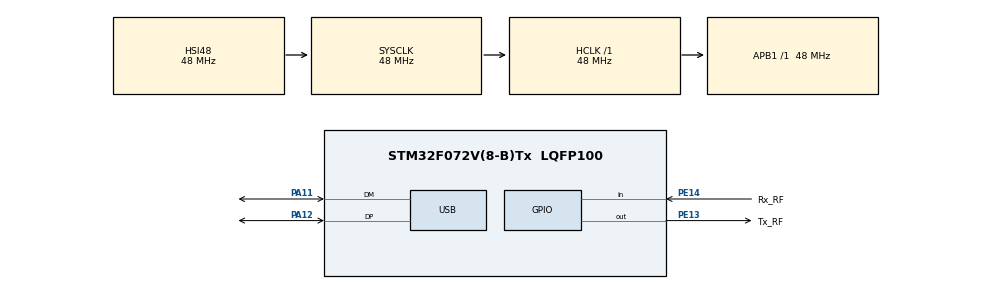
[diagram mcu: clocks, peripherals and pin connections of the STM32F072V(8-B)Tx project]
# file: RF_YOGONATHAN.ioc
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Mcu.Family=STM32F0
Mcu.Name=STM32F072V(8-B)Tx
Mcu.Package=LQFP100
NVIC.TIM7_IRQn=true\:0\:0\:false\:false\:true\:true\:true\:true
NVIC.USB_IRQn=true\:0\:0\:false\:false\:true\:false\:true\:true
PA11.Mode=Device
PA11.Signal=USB_DM
PA12.Mode=Device
PA12.Signal=USB_DP
PE13.GPIO_Label=Tx_RF
PE13.Signal=GPIO_Output
PE14.GPIO_Label=Rx_RF
PE14.Signal=GPIO_Input
ProjectManager.HeapSize=0x200
ProjectManager.StackSize=0x400
ProjectManager.TargetToolchain=STM32CubeIDE
RCC.AHBFreq_Value=48000000
RCC.APB1Freq_Value=48000000
RCC.APB1TimFreq_Value=48000000
RCC.HCLKFreq_Value=48000000
RCC.PLLSourceVirtual=RCC_PLLSOURCE_HSI48
RCC.SYSCLKFreq_VALUE=48000000
RCC.SYSCLKSource=RCC_SYSCLKSOURCE_HSI48
TIM7.Period=2975
USB_DEVICE.CLASS_NAME_FS=CDC
USB_DEVICE.VirtualMode=Cdc
USB_DEVICE.VirtualModeFS=Cdc_FS
VP_TIM7_VS_ClockSourceINT.Mode=Enable_Timer
VP_USB_DEVICE_VS_USB_DEVICE_CDC_FS.Mode=CDC_FS
board=custom

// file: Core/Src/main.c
/* USER CODE BEGIN Header */
/**
  ******************************************************************************
  * @file           : main.c
  * @brief          : Main program body
  ******************************************************************************
  * @attention
  *
  * Copyright (c) 2023 STMicroelectronics.
  * All rights reserved.
  *
  * This software is licensed under terms that can be found in the LICENSE file
  * in the root directory of this software component.
  * If no LICENSE file comes with this software, it is provided AS-IS.
  *
  ******************************************************************************
  */
/* USER CODE END Header */
#include "main.h"
#include "usb_device.h"

/* USER CODE BEGIN Includes */
#include "stdio.h"
#include "RH_ASK.h"

/* USER CODE END Includes */

TIM_HandleTypeDef htim7;

/* USER CODE BEGIN PV */

volatile uint32_t g_timerCount = 0;

uint32_t Count = 0;
uint8_t len=0, aMsgBuf[50] = {0};

uint8_t buf[RH_ASK_MAX_MESSAGE_LEN] = {0};
uint8_t buflen = 0;

/* USER CODE END PV */

void SystemClock_Config(void);
static void MX_GPIO_Init(void);
static void MX_TIM7_Init(void);

int main(void)
{

  /* MCU Configuration--------------------------------------------------------*/

  /* Reset of all peripherals, Initializes the Flash interface and the Systick. */
  HAL_Init();

  /* Configure the system clock */
  SystemClock_Config();

  /* Initialize all configured peripherals */
  MX_GPIO_Init();
  MX_TIM7_Init();
  MX_USB_DEVICE_Init();
  /* USER CODE BEGIN 2 */
  HAL_TIM_Base_Start_IT(&htim7);
//  HAL_UART_Transmit(&huart2, (uint8_t *)"/--------------------------------------------------------------/\r", 65, 1000);
//  HAL_UART_Transmit(&huart2, (uint8_t *)"               RF 433Mhz Receiver Test Application              \r", 65, 1000);
//  HAL_UART_Transmit(&huart2, (uint8_t *)"/--------------------------------------------------------------/\r", 65, 1000);

  RH_ASK_Initialization();

  /* USER CODE END 2 */

  /* Infinite loop */
  /* USER CODE BEGIN WHILE */

  char terminator[] = "\r\n";
  while (1)
  {
    /* USER CODE END WHILE */

    /* USER CODE BEGIN 3 */

	 // RH_send((uint8_t *)"Hello World\n", 12);
	  //HAL_Delay(2000);

	  buflen = RH_ASK_MAX_MESSAGE_LEN;
	  if(RH_recv(buf, &buflen) == True) {
//
//		  HAL_UART_Transmit(&huart2, (uint8_t *)"rxBuf :", 7, 1000);
//		  HAL_UART_Transmit(&huart2, (uint8_t *)buf, buflen, 1000);

		  CDC_Transmit_FS(buf, buflen);
		  CDC_Transmit_FS(terminator, sizeof(terminator));

  }
//	  HAL_Delay(1);
  }

  /* USER CODE END 3 */
}

void SystemClock_Config(void)
{
  RCC_OscInitTypeDef RCC_OscInitStruct = {0};
  RCC_ClkInitTypeDef RCC_ClkInitStruct = {0};
  RCC_PeriphCLKInitTypeDef PeriphClkInit = {0};

  /** Initializes the RCC Oscillators according to the specified parameters
  * in the RCC_OscInitTypeDef structure.
  */
  RCC_OscInitStruct.OscillatorType = RCC_OSCILLATORTYPE_HSI48;
  RCC_OscInitStruct.HSI48State = RCC_HSI48_ON;
  RCC_OscInitStruct.PLL.PLLState = RCC_PLL_NONE;
  if (HAL_RCC_OscConfig(&RCC_OscInitStruct) != HAL_OK)
  {
    Error_Handler();
  }

  /** Initializes the CPU, AHB and APB buses clocks
  */
  RCC_ClkInitStruct.ClockType = RCC_CLOCKTYPE_HCLK|RCC_CLOCKTYPE_SYSCLK
                              |RCC_CLOCKTYPE_PCLK1;
  RCC_ClkInitStruct.SYSCLKSource = RCC_SYSCLKSOURCE_HSI48;
  RCC_ClkInitStruct.AHBCLKDivider = RCC_SYSCLK_DIV1;
  RCC_ClkInitStruct.APB1CLKDivider = RCC_HCLK_DIV1;

  if (HAL_RCC_ClockConfig(&RCC_ClkInitStruct, FLASH_LATENCY_1) != HAL_OK)
  {
    Error_Handler();
  }
  PeriphClkInit.PeriphClockSelection = RCC_PERIPHCLK_USB;
  PeriphClkInit.UsbClockSelection = RCC_USBCLKSOURCE_HSI48;

  if (HAL_RCCEx_PeriphCLKConfig(&PeriphClkInit) != HAL_OK)
  {
    Error_Handler();
  }
}

static void MX_TIM7_Init(void)
{

  TIM_MasterConfigTypeDef sMasterConfig = {0};

  htim7.Instance = TIM7;
  htim7.Init.Prescaler = 0;
  htim7.Init.CounterMode = TIM_COUNTERMODE_UP;
  htim7.Init.Period = 2975;
  htim7.Init.AutoReloadPreload = TIM_AUTORELOAD_PRELOAD_DISABLE;
  if (HAL_TIM_Base_Init(&htim7) != HAL_OK)
  {
    Error_Handler();
  }
  sMasterConfig.MasterOutputTrigger = TIM_TRGO_RESET;
  sMasterConfig.MasterSlaveMode = TIM_MASTERSLAVEMODE_DISABLE;
  if (HAL_TIMEx_MasterConfigSynchronization(&htim7, &sMasterConfig) != HAL_OK)
  {
    Error_Handler();
  }

}

static void MX_GPIO_Init(void)
{
  GPIO_InitTypeDef GPIO_InitStruct = {0};

  /* GPIO Ports Clock Enable */
  __HAL_RCC_GPIOE_CLK_ENABLE();
  __HAL_RCC_GPIOA_CLK_ENABLE();

  /*Configure GPIO pin Output Level */
  HAL_GPIO_WritePin(Tx_RF_GPIO_Port, Tx_RF_Pin, GPIO_PIN_RESET);

  /*Configure GPIO pin : Tx_RF_Pin */
  GPIO_InitStruct.Pin = Tx_RF_Pin;
  GPIO_InitStruct.Mode = GPIO_MODE_OUTPUT_PP;
  GPIO_InitStruct.Pull = GPIO_NOPULL;
  GPIO_InitStruct.Speed = GPIO_SPEED_FREQ_LOW;
  HAL_GPIO_Init(Tx_RF_GPIO_Port, &GPIO_InitStruct);

  /*Configure GPIO pin : Rx_RF_Pin */
  GPIO_InitStruct.Pin = Rx_RF_Pin;
  GPIO_InitStruct.Mode = GPIO_MODE_INPUT;
  GPIO_InitStruct.Pull = GPIO_NOPULL;
  HAL_GPIO_Init(Rx_RF_GPIO_Port, &GPIO_InitStruct);

}

void Error_Handler(void)
{
  __disable_irq();
  while (1)
  {
  }
}
